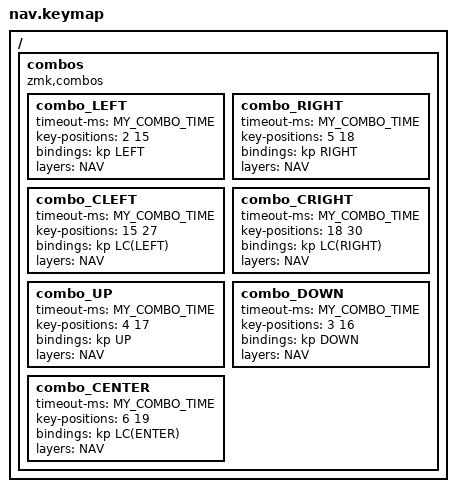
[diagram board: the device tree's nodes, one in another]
/ {
    combos {
        compatible = "zmk,combos";
        combo_LEFT {
            timeout-ms = <MY_COMBO_TIME>;
            key-positions = <2 15>;
            bindings = <&kp LEFT>;
            layers = <NAV>;
        };
        combo_RIGHT {
            timeout-ms = <MY_COMBO_TIME>;
            key-positions = <5 18>;
            bindings = <&kp RIGHT>;
            layers = <NAV>;
        };
        combo_CLEFT {
            timeout-ms = <MY_COMBO_TIME>;
            key-positions = <15 27>;
            bindings = <&kp LC(LEFT)>;
            layers = <NAV>;
        };
        combo_CRIGHT {
            timeout-ms = <MY_COMBO_TIME>;
            key-positions = <18 30>;
            bindings = <&kp LC(RIGHT)>;
            layers = <NAV>;
        };
        combo_UP {
            timeout-ms = <MY_COMBO_TIME>;
            key-positions = <4 17>;
            bindings = <&kp UP>;
            layers = <NAV>;
        };
        combo_DOWN {
            timeout-ms = <MY_COMBO_TIME>;
            key-positions = <3 16>;
            bindings = <&kp DOWN>;
            layers = <NAV>;
        };
        combo_CENTER {
            timeout-ms = <MY_COMBO_TIME>;
            key-positions = <6 19>;
            bindings = <&kp LC(ENTER)>;
            layers = <NAV>;
        };
    };
};
